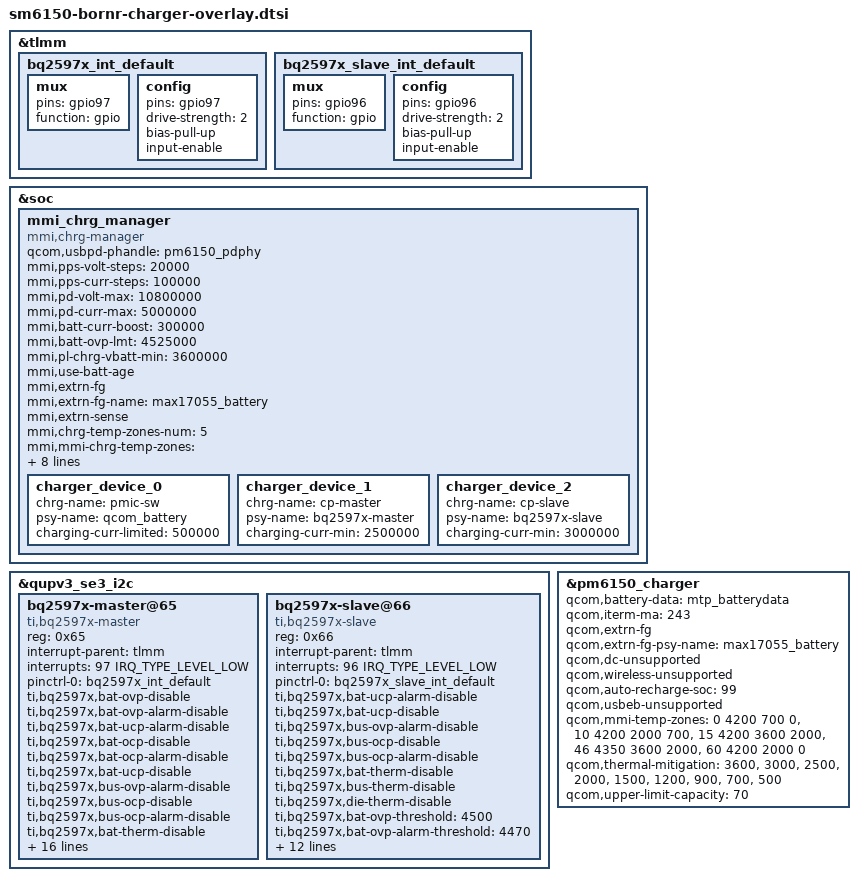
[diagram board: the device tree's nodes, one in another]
#include <dt-bindings/gpio/gpio.h>
#include <dt-bindings/pinctrl/qcom,pmic-gpio.h>

&tlmm{
	bq2597x_int_default: bq2597x_int_default {
		mux {
			pins = "gpio97";
			function = "gpio";
		};

		config {
			pins = "gpio97";
			drive-strength = <2>; /* 2 MA */
			bias-pull-up;
			input-enable;
		};
	};

	bq2597x_slave_int_default: bq2597x_slave_int_default {
		mux {
			pins = "gpio96";
			function = "gpio";
		};

		config {
			pins = "gpio96";
			drive-strength = <2>; /* 2 MA */
			bias-pull-up;
			input-enable;
		};
	};


};

&soc {
	mmi_chrg_manager {
		compatible = "mmi,chrg-manager";
		qcom,usbpd-phandle = <&pm6150_pdphy>;
		mmi,pps-volt-steps = <20000>;
		mmi,pps-curr-steps = <100000>;
		mmi,pd-volt-max = <10800000>;
		mmi,pd-curr-max = <5000000>;
		mmi,batt-curr-boost = <300000>;
		mmi,batt-ovp-lmt = <4525000>;
		mmi,pl-chrg-vbatt-min = <3600000>;
		mmi,use-batt-age;
		mmi,extrn-fg;
		mmi,extrn-fg-name = "max17055_battery";
		mmi,extrn-sense;
		mmi,chrg-temp-zones-num = <5>;
		mmi,mmi-chrg-temp-zones =
					<0 4200 700 0 0 0 0 0 0>,
					<10 4200 2000 4400 700 0 0 0 0>,
					<15 4200 6000 4400 2000 0 0 0 0>,
					<45 4250 8000 4300 6000 4350 4000 4400 2000>,
					<60 4200 2000 0 0 0 0 0 0>;
		mmi,thermal-mitigation =
					<10000000>,
					<8000000>,
					<7000000>,
					<6000000>,
					<5000000>,
					<4000000>,
					<3000000>,
					<2000000>;
		charger_device_0 {
			chrg-name = "pmic-sw";
			psy-name = "qcom_battery";
			charging-curr-limited = <500000>;
		};
		charger_device_1 {
			chrg-name = "cp-master";
			psy-name = "bq2597x-master";
			charging-curr-min = <2500000>;
		};
		charger_device_2 {
			chrg-name = "cp-slave";
			psy-name = "bq2597x-slave";
			charging-curr-min = <3000000>;
		};
	};
};

&qupv3_se3_i2c {
	bq2597x-master@65 {
		compatible = "ti,bq2597x-master";
		reg = <0x65>;

		/delete-property/ interrupts;
		interrupt-parent = <&tlmm>;
		interrupts = <97 IRQ_TYPE_LEVEL_LOW>;
		pinctrl-names = "default";
		pinctrl-0 = <&bq2597x_int_default>;
		ti,bq2597x,bat-ovp-disable;
		ti,bq2597x,bat-ovp-alarm-disable;
		ti,bq2597x,bat-ucp-alarm-disable;
		ti,bq2597x,bat-ocp-disable;
		ti,bq2597x,bat-ocp-alarm-disable;

		ti,bq2597x,bat-ucp-disable;

		ti,bq2597x,bus-ovp-alarm-disable;
		ti,bq2597x,bus-ocp-disable;
		ti,bq2597x,bus-ocp-alarm-disable;


		ti,bq2597x,bat-therm-disable;
		ti,bq2597x,bus-therm-disable;
		ti,bq2597x,die-therm-disable;

		ti,bq2597x,bat-ovp-threshold = <4525>;
		ti,bq2597x,bat-ovp-alarm-threshold = <4450>;
		ti,bq2597x,bat-ocp-threshold = <11000>;
		ti,bq2597x,bat-ocp-alarm-threshold = <9500>;

		ti,bq2597x,bus-ovp-threshold = <12000>;
		ti,bq2597x,bus-ovp-alarm-threshold = <11000>;
		ti,bq2597x,bus-ocp-threshold = <4750>;
		ti,bq2597x,bus-ocp-alarm-threshold = <4500>;

		ti,bq2597x,bat-ucp-alarm-threshold = <2000>;

		ti,bq2597x,bat-therm-threshold = <0x15>;/*4.1%*/
		ti,bq2597x,bus-therm-threshold = <0x15>;/*4.1%*/
		ti,bq2597x,die-therm-threshold = <125>;

		ti,bq2597x,ac-ovp-threshold = <17>;
		ti,bq2597x,sense-resistor-mohm = <2>;

	};

	bq2597x-slave@66 {
		compatible = "ti,bq2597x-slave";
		reg = <0x66>;
		/delete-property/ interrupts;
		interrupt-parent = <&tlmm>;
		interrupts = <96 IRQ_TYPE_LEVEL_LOW>;
		pinctrl-names = "default";
		pinctrl-0 = <&bq2597x_slave_int_default>;

		ti,bq2597x,bat-ucp-alarm-disable;

		ti,bq2597x,bat-ucp-disable;

		ti,bq2597x,bus-ovp-alarm-disable;
		ti,bq2597x,bus-ocp-disable;
		ti,bq2597x,bus-ocp-alarm-disable;

		ti,bq2597x,bat-therm-disable;
		ti,bq2597x,bus-therm-disable;
		ti,bq2597x,die-therm-disable;

		ti,bq2597x,bat-ovp-threshold = <4500>;
		ti,bq2597x,bat-ovp-alarm-threshold = <4470>;
		ti,bq2597x,bat-ocp-threshold = <10000>;
		ti,bq2597x,bat-ocp-alarm-threshold = <9500>;

		ti,bq2597x,bus-ovp-threshold = <12000>;
		ti,bq2597x,bus-ovp-alarm-threshold = <11000>;
		ti,bq2597x,bus-ocp-threshold = <4750>;
		ti,bq2597x,bus-ocp-alarm-threshold = <4500>;

		ti,bq2597x,bat-ucp-alarm-threshold = <2000>;

		ti,bq2597x,bat-therm-threshold = <0x15>;/*4.1%*/
		ti,bq2597x,bus-therm-threshold = <0x15>;/*4.1%*/
		ti,bq2597x,die-therm-threshold = <125>;

		ti,bq2597x,ac-ovp-threshold = <12>;
		ti,bq2597x,sense-resistor-mohm = <2>;

	};
};

&pm6150_charger {
	qcom,battery-data = <&mtp_batterydata>;
	qcom,iterm-ma = <243>;
	qcom,extrn-fg;
	qcom,extrn-fg-psy-name = "max17055_battery";
	qcom,dc-unsupported;
	qcom,wireless-unsupported;
	qcom,auto-recharge-soc = <99>;
	qcom,usbeb-unsupported;
	qcom,mmi-temp-zones = <0 4200 700 0>,
				<10 4200 2000 700>,
				<15 4200 3600 2000>,
				<46 4350 3600 2000>,
				<60 4200 2000 0>;
	qcom,thermal-mitigation = <3600>,
				   <3000>,
				   <2500>,
				   <2000>,
				   <1500>,
				   <1200>,
				   <900>,
				   <700>,
				   <500>;
	qcom,upper-limit-capacity = <70>;
};

